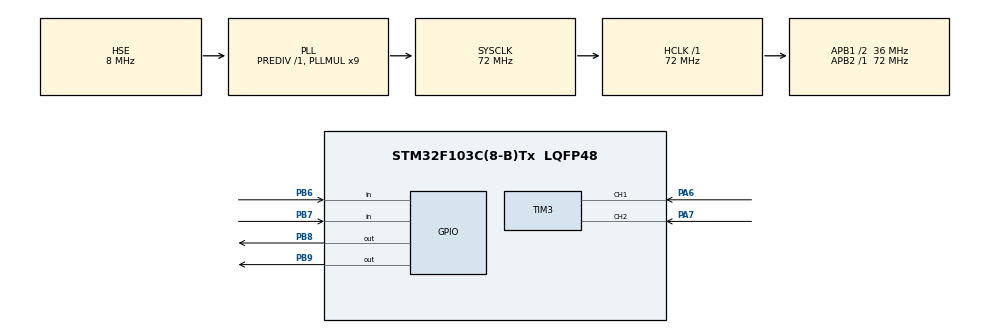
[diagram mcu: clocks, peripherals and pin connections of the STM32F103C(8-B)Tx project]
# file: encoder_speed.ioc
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Mcu.Family=STM32F1
Mcu.Name=STM32F103C(8-B)Tx
Mcu.Package=LQFP48
NVIC.PriorityGroup=NVIC_PRIORITYGROUP_4
NVIC.TIM2_IRQn=true\:0\:0\:false\:false\:true\:true\:true\:true
PA13.Mode=Serial_Wire
PA13.Signal=SYS_JTMS-SWDIO
PA14.Mode=Serial_Wire
PA14.Signal=SYS_JTCK-SWCLK
PA6.Signal=S_TIM3_CH1
PA7.Signal=S_TIM3_CH2
PB6.GPIO_PuPd=GPIO_PULLUP
PB6.Signal=GPIO_Input
PB7.GPIO_PuPd=GPIO_PULLUP
PB7.Signal=GPIO_Input
PB8.GPIO_ModeDefaultOutputPP=GPIO_MODE_OUTPUT_OD
PB8.GPIO_PuPd=GPIO_NOPULL
PB8.Signal=GPIO_Output
PB9.GPIO_ModeDefaultOutputPP=GPIO_MODE_OUTPUT_OD
PB9.GPIO_PuPd=GPIO_NOPULL
PB9.Signal=GPIO_Output
PD0-OSC_IN.Mode=HSE-External-Oscillator
PD0-OSC_IN.Signal=RCC_OSC_IN
PD1-OSC_OUT.Mode=HSE-External-Oscillator
PD1-OSC_OUT.Signal=RCC_OSC_OUT
ProjectManager.HeapSize=0x200
ProjectManager.StackSize=0x400
ProjectManager.TargetToolchain=STM32CubeIDE
RCC.AHBFreq_Value=72000000
RCC.APB1CLKDivider=RCC_HCLK_DIV2
RCC.APB1Freq_Value=36000000
RCC.APB1TimFreq_Value=72000000
RCC.APB2Freq_Value=72000000
RCC.APB2TimFreq_Value=72000000
RCC.HCLKFreq_Value=72000000
RCC.PLLMUL=RCC_PLL_MUL9
RCC.PLLSourceVirtual=RCC_PLLSOURCE_HSE
RCC.SYSCLKFreq_VALUE=72000000
RCC.SYSCLKSource=RCC_SYSCLKSOURCE_PLLCLK
RCC.USBFreq_Value=72000000
SH.S_TIM3_CH1.0=TIM3_CH1,Encoder_Interface
SH.S_TIM3_CH2.0=TIM3_CH2,Encoder_Interface
TIM2.AutoReloadPreload=TIM_AUTORELOAD_PRELOAD_ENABLE
TIM2.Period=10000 - 1
TIM2.Prescaler=7200 - 1
TIM3.EncoderMode=TIM_ENCODERMODE_TI12
VP_TIM2_VS_ClockSourceINT.Mode=Internal
board=custom

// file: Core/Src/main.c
/* USER CODE BEGIN Header */
/**
  ******************************************************************************
  * @file           : main.c
  * @brief          : Main program body
  ******************************************************************************
  * @attention
  *
  * Copyright (c) 2026 STMicroelectronics.
  * All rights reserved.
  *
  * This software is licensed under terms that can be found in the LICENSE file
  * in the root directory of this software component.
  * If no LICENSE file comes with this software, it is provided AS-IS.
  *
  ******************************************************************************
  */
/* USER CODE END Header */
#include "main.h"
#include "tim.h"
#include "gpio.h"

/* USER CODE BEGIN PV */
int16_t Speed = 0;
/* USER CODE END PV */

void SystemClock_Config(void);

/* USER CODE BEGIN 0 */
int16_t GetEncoderSpeed()
{
	uint16_t Temp;
	Temp = __HAL_TIM_GET_COUNTER(&htim3);
	__HAL_TIM_SET_COUNTER(&htim3, 0);
	return Temp;
}
/* USER CODE END 0 */

int main(void)
{

  /* MCU Configuration--------------------------------------------------------*/

  /* Reset of all peripherals, Initializes the Flash interface and the Systick. */
  HAL_Init();

  /* Configure the system clock */
  SystemClock_Config();

  /* Initialize all configured peripherals */
  MX_GPIO_Init();
  MX_TIM3_Init();
  MX_TIM2_Init();

  /* Infinite loop */
  /* USER CODE BEGIN WHILE */
	OLED_Init();
	HAL_TIM_Encoder_Start(&htim3, TIM_CHANNEL_ALL);
	HAL_TIM_Base_Start_IT(&htim2);
	OLED_Clear();
	OLED_ShowString(1, 1, "Speed:");

  while (1)
  {
		OLED_ShowSignedNum(1,7,Speed,5);
    /* USER CODE END WHILE */

  }
}

void SystemClock_Config(void)
{
  RCC_OscInitTypeDef RCC_OscInitStruct = {0};
  RCC_ClkInitTypeDef RCC_ClkInitStruct = {0};

  /** Initializes the RCC Oscillators according to the specified parameters
  * in the RCC_OscInitTypeDef structure.
  */
  RCC_OscInitStruct.OscillatorType = RCC_OSCILLATORTYPE_HSE;
  RCC_OscInitStruct.HSEState = RCC_HSE_ON;
  RCC_OscInitStruct.HSEPredivValue = RCC_HSE_PREDIV_DIV1;
  RCC_OscInitStruct.HSIState = RCC_HSI_ON;
  RCC_OscInitStruct.PLL.PLLState = RCC_PLL_ON;
  RCC_OscInitStruct.PLL.PLLSource = RCC_PLLSOURCE_HSE;
  RCC_OscInitStruct.PLL.PLLMUL = RCC_PLL_MUL9;
  if (HAL_RCC_OscConfig(&RCC_OscInitStruct) != HAL_OK)
  {
    Error_Handler();
  }

  /** Initializes the CPU, AHB and APB buses clocks
  */
  RCC_ClkInitStruct.ClockType = RCC_CLOCKTYPE_HCLK|RCC_CLOCKTYPE_SYSCLK
                              |RCC_CLOCKTYPE_PCLK1|RCC_CLOCKTYPE_PCLK2;
  RCC_ClkInitStruct.SYSCLKSource = RCC_SYSCLKSOURCE_PLLCLK;
  RCC_ClkInitStruct.AHBCLKDivider = RCC_SYSCLK_DIV1;
  RCC_ClkInitStruct.APB1CLKDivider = RCC_HCLK_DIV2;
  RCC_ClkInitStruct.APB2CLKDivider = RCC_HCLK_DIV1;

  if (HAL_RCC_ClockConfig(&RCC_ClkInitStruct, FLASH_LATENCY_2) != HAL_OK)
  {
    Error_Handler();
  }
}

void Error_Handler(void)
{
  __disable_irq();
  while (1)
  {
  }
}
